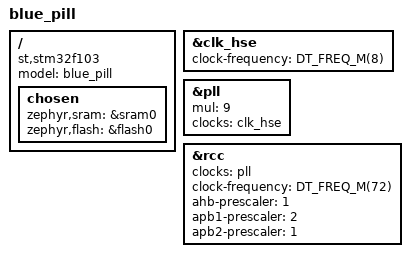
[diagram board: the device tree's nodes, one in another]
/*
 * Copyright (c) 2023 Quasal
 *
 * SPDX-License-Identifier: Apache-2.0
 */

/dts-v1/;
#include <st/f1/stm32f103X8.dtsi>

/ {
    model = "blue_pill";
    compatible = "st,stm32f103";

    chosen {
        zephyr,sram = &sram0;
        zephyr,flash = &flash0;
    };
};

&clk_hse {
    clock-frequency = <DT_FREQ_M(8)>;
    status = "okay";
};

&pll {
    mul = <9>;
    clocks = <&clk_hse>;
    status = "okay";
};

&rcc {
    clocks = <&pll>;
    clock-frequency = <DT_FREQ_M(72)>;
    ahb-prescaler = <1>;
    apb1-prescaler = <2>;
    apb2-prescaler = <1>;
    status = "okay";
};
